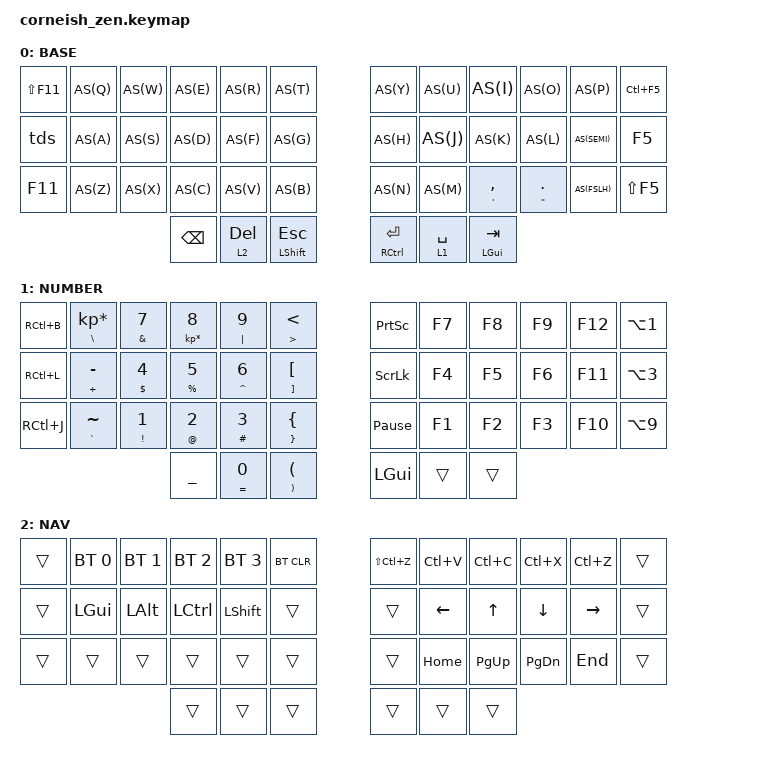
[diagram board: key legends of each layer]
#include <behaviors.dtsi>
#include <dt-bindings/zmk/keys.h>
#include <dt-bindings/zmk/bt.h>

#define AS(keycode) &as LS(keycode) keycode

/ {
        chosen {
                zmk,matrix_transform = &default_transform;
                //zmk,matrix_transform =  &five_column_transform;
        };
};

&mt {
        tapping-term-ms = <140>;
};

/ {
        behaviors {
                as: auto_shift {
                        label = "AUTO_SHIFT";
                        compatible = "zmk,behavior-hold-tap";
                        #binding-cells = <2>;
                        tapping_term_ms = <140>;
                        quick_tap_ms = <0>;
                        flavor = "tap-preferred";
                        bindings = <&kp>, <&kp>;
                };
                tds: tap_dance_step {
                        compatible = "zmk,behavior-tap-dance";
                        label = "TAP_DANCE_0";
                        #binding-cells = <0>;
                        tapping-term-ms = <230>;
                        bindings = <&kp F10>, <&kp F5>;
                };
        };

        macros {
                COMMIT: git-commit {
                        label = "git-commit";
                        compatible = "zmk,behavior-macro";
                        #binding-cells = <0>;
                        bindings = <&macro_tap &kp LC(K)>;
                };
        };

        keymap {
                compatible = "zmk,keymap";

                default_layer {
                        label = "BASE";
                        //  ------------------------------------------------------------------------------------------------
                        // | SOUT  |  Q  |  W  |  E  |    R   |    T   |     |   Y    |    U   |   I    |  O  |  P  | RUN   |
                        // | SOVER |  A  |  S  |  D  |    F   |    G   |     |   H    |    J   |   K    |  L  |  ;: | DEBUG |
                        // | SINTO |  Z  |  X  |  C  |    V   |    B   |     |   N    |    M   |   ,'   |  ." |  /? | STOP  |
                        //                     | BCK | DEL[2] | ESC[S] |     | ENT[C] | SPC[1] | TAB[G] |
                        //
                        bindings = <
                                &kp LS(F11) AS(Q)  AS(W)  AS(E)  AS(R)  AS(T)  AS(Y)  AS(U)  AS(I)           AS(O)        AS(P)     &kp LC(F5)
                                &tds        AS(A)  AS(S)  AS(D)  AS(F)  AS(G)  AS(H)  AS(J)  AS(K)           AS(L)        AS(SEMI)  &kp F5
                                &kp F11     AS(Z)  AS(X)  AS(C)  AS(V)  AS(B)  AS(N)  AS(M)  &mt APOS COMMA  &mt DQT DOT  AS(FSLH)  &kp LS(F5)
                                &kp BSPC    &lt 2 DEL   &mt LSHIFT ESC            &mt RCTRL RET   &lt 1 SPACE   &mt LGUI TAB
                        >;
                };

                number_layer {
                        label = "NUMBER";
                        //  -----------------------------------------------------------------------------
                        // | LPanel | *\ | 7& | 8* | 9| | <> |    | SHFT | F7 | F8 | F9 | F12 | Explorer |
                        // | RPanel | -+ | 4$ | 5% | 6^ | [] |    | ALT  | F4 | F5 | F6 | F11 | Search   |
                        // | BPanel | ~` | 1! | 2@ | 3# | {} |    | CTRL | F1 | F2 | F3 | F10 | Source   |
                        //                    | _  | 0= | () |    | GUI  |    |    |
                        //
                        bindings = <
                                &kp RC(B)  &mt BSLH KP_MULTIPLY  &mt AMPS N7  &mt KP_MULTIPLY N8  &mt PIPE N9   &mt GT LT      &kp PRINTSCREEN  &kp F7  &kp F8  &kp F9  &kp F12  &kp LA(N1)
                                &kp RC(L)  &mt PLUS MINUS        &mt DLLR N4  &mt PRCNT N5        &mt CARET N6  &mt RBKT LBKT  &kp SCROLLLOCK   &kp F4  &kp F5  &kp F6  &kp F11  &kp LA(N3)
                                &kp RC(J)  &mt GRAVE TILDE       &mt EXCL N1  &mt AT N2           &mt HASH N3   &mt RBRC LBRC  &kp PAUSE_BREAK  &kp F1  &kp F2  &kp F3  &kp F10  &kp LA(N9)
                                           &kp UNDER   &mt EQUAL N0   &mt RPAR LPAR               &kp LGUI   &trans   &trans
                        >;
                };

                nav_layer {
                        label = "NAV";
                        //  -----------------------------------------------------------------------------
                        // |      | BT1 | BT2 | BT3  | BT4  | BCR |    | Redo | Paste | Copy | Cut  | Undo |    |
                        // |      | GUI | ALT | CTRL | SHFT |     |    |      |   ←   |  ↑   |  ↓   |  →   |    |
                        // |      |     |     |      |      |     |    |      |  HOME | PgUp | PgDn | End  |    |
                        //                    |      |      |     |    |      |       |      |
                        //
                        bindings = <
                                &trans &bt BT_SEL 0 &bt BT_SEL 1 &bt BT_SEL 2 &bt BT_SEL 3 &bt BT_CLR  &kp LS(LC(Z))  &kp LC(V)     &kp LC(C)     &kp LC(X)    &kp LC(Z)    &trans
                                &trans     &kp LGUI     &kp LALT     &kp LCTRL    &kp LSHFT    &trans       &trans         &kp LEFT      &kp UP        &kp DOWN     &kp RIGHT    &trans
                                &trans     &trans       &trans       &trans       &trans       &trans       &trans         &kp HOME      &kp PG_UP     &kp PG_DN    &kp END      &trans
                                           &trans       &trans       &trans                                 &trans   &trans   &trans
                        >;
                };
        };
};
